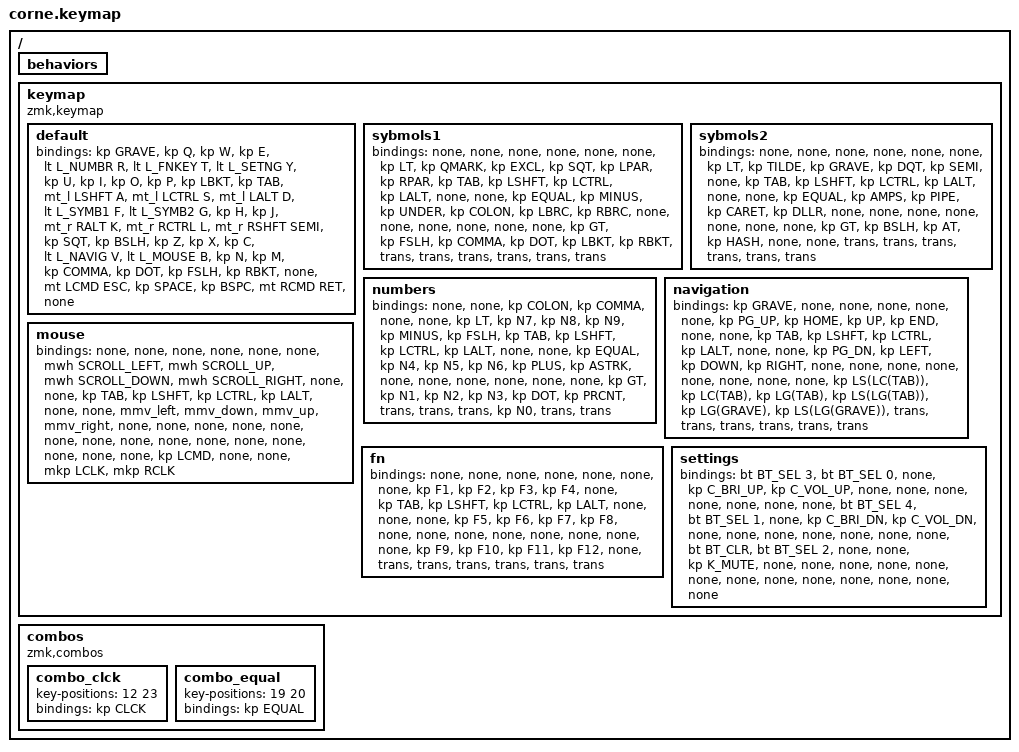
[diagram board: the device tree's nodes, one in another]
#include <behaviors.dtsi>
#include <dt-bindings/zmk/keys.h>
#include <dt-bindings/zmk/mouse.h>
#include <dt-bindings/zmk/bt.h>
#include "behaviors.dtsi"

#define L_DEFLT 0
#define L_SYMB1 1
#define L_SYMB2 2
#define L_NUMBR 3
#define L_NAVIG 4
#define L_MOUSE 5
#define L_FNKEY 6
#define L_SETNG 7

/ {

  behaviors {
  };

  keymap {
    compatible = "zmk,keymap";

    default {
      bindings = <

        &kp GRAVE
        &kp Q
        &kp W
        &kp E
        &lt L_NUMBR R
        &lt L_FNKEY T

        &lt L_SETNG Y
        &kp U
        &kp I
        &kp O
        &kp P
        &kp LBKT

        &kp TAB
        &mt_l LSHFT A
        &mt_l LCTRL S
        &mt_l LALT D
        &lt L_SYMB1 F
        &lt L_SYMB2 G

        &kp H
        &kp J
        &mt_r RALT K
        &mt_r RCTRL L
        &mt_r RSHFT SEMI
        &kp SQT

        &kp BSLH
        &kp Z
        &kp X
        &kp C
        &lt L_NAVIG V
        &lt L_MOUSE B

        &kp N
        &kp M
        &kp COMMA
        &kp DOT
        &kp FSLH
        &kp RBKT

        &none
        &mt LCMD ESC
        &kp SPACE

        &kp BSPC
        &mt RCMD RET
        &none

      >;
    };

    sybmols1 {
      bindings = <

        &none
        &none
        &none
        &none
        &none
        &none

        &kp LT
        &kp QMARK
        &kp EXCL
        &kp SQT
        &kp LPAR
        &kp RPAR

        &kp TAB
        &kp LSHFT
        &kp LCTRL
        &kp LALT
        &none
        &none

        &kp EQUAL
        &kp MINUS
        &kp UNDER
        &kp COLON
        &kp LBRC
        &kp RBRC

        &none
        &none
        &none
        &none
        &none
        &none

        &kp GT
        &kp FSLH
        &kp COMMA
        &kp DOT
        &kp LBKT
        &kp RBKT

        &trans
        &trans
        &trans

        &trans
        &trans
        &trans

      >;
    };

    sybmols2 {
      bindings = <

        &none
        &none
        &none
        &none
        &none
        &none

        &kp LT
        &kp TILDE
        &kp GRAVE
        &kp DQT
        &kp SEMI
        &none

        &kp TAB
        &kp LSHFT
        &kp LCTRL
        &kp LALT
        &none
        &none

        &kp EQUAL
        &kp AMPS
        &kp PIPE
        &kp CARET
        &kp DLLR
        &none

        &none
        &none
        &none
        &none
        &none
        &none

        &kp GT
        &kp BSLH
        &kp AT
        &kp HASH
        &none
        &none

        &trans
        &trans
        &trans

        &trans
        &trans
        &trans

      >;
    };

    numbers {
      bindings = <

        &none
        &none
        &kp COLON
        &kp COMMA
        &none
        &none

        &kp LT
        &kp N7
        &kp N8
        &kp N9
        &kp MINUS
        &kp FSLH

        &kp TAB
        &kp LSHFT
        &kp LCTRL
        &kp LALT
        &none
        &none

        &kp EQUAL
        &kp N4
        &kp N5
        &kp N6
        &kp PLUS
        &kp ASTRK

        &none
        &none
        &none
        &none
        &none
        &none

        &kp GT
        &kp N1
        &kp N2
        &kp N3
        &kp DOT
        &kp PRCNT

        &trans
        &trans
        &trans

        &kp N0
        &trans
        &trans

      >;
    };

    navigation {
      bindings = <

        &kp GRAVE
        &none
        &none
        &none
        &none
        &none

        &kp PG_UP
        &kp HOME
        &kp UP
        &kp END
        &none
        &none

        &kp TAB
        &kp LSHFT
        &kp LCTRL
        &kp LALT
        &none
        &none

        &kp PG_DN
        &kp LEFT
        &kp DOWN
        &kp RIGHT
        &none
        &none

        &none
        &none
        &none
        &none
        &none
        &none

        &kp LS(LC(TAB))
        &kp LC(TAB)
        &kp LG(TAB)
        &kp LS(LG(TAB))
        &kp LG(GRAVE)
        &kp LS(LG(GRAVE))

        &trans
        &trans
        &trans

        &trans
        &trans
        &trans

      >;
    };

    mouse {
      bindings = <

        &none
        &none
        &none
        &none
        &none
        &none

        &mwh SCROLL_LEFT
        &mwh SCROLL_UP
        &mwh SCROLL_DOWN
        &mwh SCROLL_RIGHT
        &none
        &none

        &kp TAB
        &kp LSHFT
        &kp LCTRL
        &kp LALT
        &none
        &none

        &mmv_left
        &mmv_down
        &mmv_up
        &mmv_right
        &none
        &none

        &none
        &none
        &none
        &none
        &none
        &none

        &none
        &none
        &none
        &none
        &none
        &none

        &none
        &kp LCMD
        &none

        &none
        &mkp LCLK
        &mkp RCLK

      >;
    };

    fn {
      bindings = <

        &none
        &none
        &none
        &none
        &none
        &none

        &none
        &kp F1
        &kp F2
        &kp F3
        &kp F4
        &none

        &kp TAB
        &kp LSHFT
        &kp LCTRL
        &kp LALT
        &none
        &none

        &none
        &kp F5
        &kp F6
        &kp F7
        &kp F8
        &none

        &none
        &none
        &none
        &none
        &none
        &none

        &none
        &kp F9
        &kp F10
        &kp F11
        &kp F12
        &none

        &trans
        &trans
        &trans

        &trans
        &trans
        &trans

      >;
    };

    settings {
      bindings = <

        &bt BT_SEL 3
        &bt BT_SEL 0
        &none
        &kp C_BRI_UP
        &kp C_VOL_UP
        &none

        &none
        &none
        &none
        &none
        &none
        &none

        &bt BT_SEL 4
        &bt BT_SEL 1
        &none
        &kp C_BRI_DN
        &kp C_VOL_DN
        &none

        &none
        &none
        &none
        &none
        &none
        &none

        &bt BT_CLR
        &bt BT_SEL 2
        &none
        &none
        &kp K_MUTE
        &none

        &none
        &none
        &none
        &none
        &none
        &none

        &none
        &none
        &none

        &none
        &none
        &none

      >;
    };

  };

  combos {
    compatible = "zmk,combos";

    combo_clck {
      key-positions = <12 23>;
      bindings = <&kp CLCK>;
    };

    combo_equal {
      key-positions = <19 20>;
      bindings = <&kp EQUAL>;
    };

  };

};
